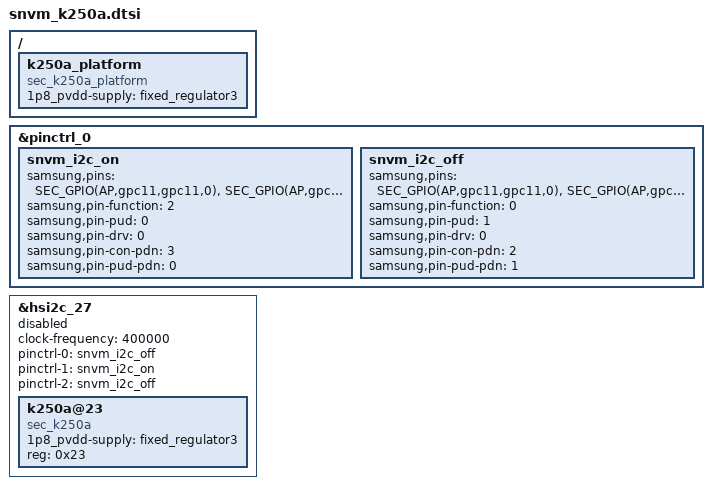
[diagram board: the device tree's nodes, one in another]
/*
 * This program is free software; you can redistribute it and/or modify
 * it under the terms of the GNU General Public License version 2 and
 * only version 2 as published by the Free Software Foundation.
 *
 * This program is distributed in the hope that it will be useful,
 * but WITHOUT ANY WARRANTY; without even the implied warranty of
 * MERCHANTABILITY or FITNESS FOR A PARTICULAR PURPOSE.  See the
 * GNU General Public License for more details.
 */

&pinctrl_0 {
	snvm_i2c_on: snvm_i2c_on {
		samsung,pins = SEC_GPIO(AP,gpc11,gpc11,0), SEC_GPIO(AP,gpc12,gpc12,0);
		samsung,pin-function = <2>;
		samsung,pin-pud = <0>;
		samsung,pin-drv = <0>;
		samsung,pin-con-pdn = <3>; /* PIN_PDN_PREV */
		samsung,pin-pud-pdn = <0>;
	};
	snvm_i2c_off: snvm_i2c_off {
		samsung,pins = SEC_GPIO(AP,gpc11,gpc11,0), SEC_GPIO(AP,gpc12,gpc12,0);
		samsung,pin-function = <0>;
		samsung,pin-pud = <1>;
		samsung,pin-drv = <0>;
		samsung,pin-con-pdn = <2>; /* PIN_PDN_INPUT */
		samsung,pin-pud-pdn = <1>;
	};
};

&hsi2c_27 {
	clock-frequency = <400000>;
#if 1	
	status = "disabled";
#else
	status = "okay";
#endif
	pinctrl-names = "default", "nvm_on","nvm_off";
	pinctrl-0 = <&snvm_i2c_off>;
	pinctrl-1 = <&snvm_i2c_on>;
	pinctrl-2 = <&snvm_i2c_off>;
	k250a@23 {
		compatible = "sec_k250a";
		1p8_pvdd-supply = <&fixed_regulator3>;
		reg = <0x23>;
	};
};

#if 1
/ {
	fragment@k250a_platform {
		target-path = "/";
		__overlay__ {
			k250a_platform {
				status = "ok";
				compatible = "sec_k250a_platform";
				1p8_pvdd-supply = <&fixed_regulator3>;
			};
		};
	};
};
#endif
